# psc3m6 register map
Vendor: Infineon Technologies; Series: PSC3M6; File version: 1.0
CPU: CM33 r0p1, little endian, MPU, FPU, DSP, VTOR, 3 interrupt priority bits, 167 interrupts
Registers are 32-bit, read-write, reset 0x0 unless marked. A register's access mark holds for its fields unless they carry their own. Offsets are from the block's base; [hi:lo] are bit positions; lines under a group give offsets from that group; {n}, {i} and the like mark numbered series; 'fields as' and 'values as' point back to an identical list.

## TCPWM0 (part 1 of 2) — S40 Timer/Counter/PWM
Base 0x42A00000
{0x0+0x10000*i} GRP[{i}] (i=0..2) group — Group of counters
  {0x0+0x100*j} CNT[{j}] (j=0..7) group — Timer/Counter/PWM Counter Module
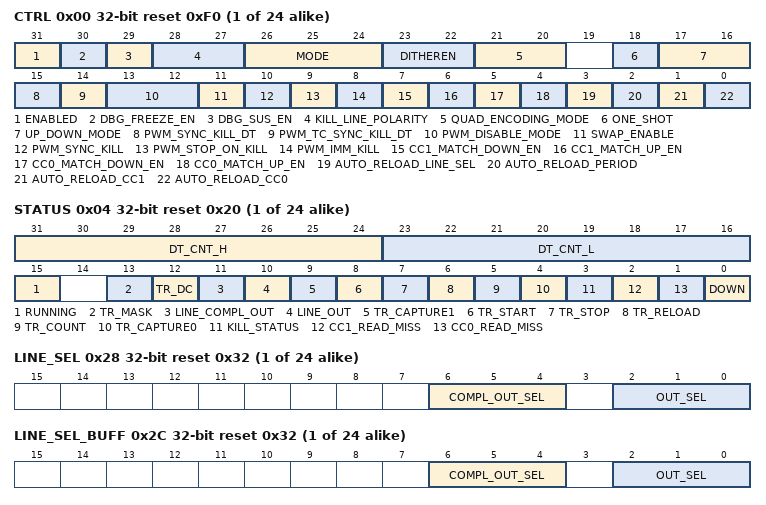
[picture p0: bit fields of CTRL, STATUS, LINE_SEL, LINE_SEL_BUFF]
    0x00 CTRL reset 0xF0 — Counter control register
      [31] ENABLED — Counter enable. '0': counter disabled. '1': counter enabled. Counter static configuration information (e.g. CTRL.MODE, all TR_IN_SEL, TR_IN_EDGE_SEL, TR_PWM_CTRL and TR_OUT_SEL register fields) should only be modified when the counter is disabled. When a counter is disabled, command and status information associated to the counter is cleared by HW, this includes: - the associated counter triggers in the CMD register are set to '0'. - the counter's interrupt cause fields in counter's INTR register. - the counter's status fields in counter's STATUS register.. - the counter's trigger outputs ('tr_out0' and tr_out1'). - the counter's line outputs ('line_out' and 'line_compl_out').
      [30] DBG_FREEZE_EN — Specifies the counter behavior in debug mode. '0': The counter operation depends on DBG_SUS_EN value, when ='0', counter operation continues; when ='1', Counter Freeze after roll over (tc event) and enters safe state. '1': The counter operation freezes in debug mode depending on DBG_SUS_EN value; when='0', Counter Freeze; when ='1', Counter Freeze immediately and enters safe state and running bit to be made ='0'. Safe state values are defined on line_out and line_compl_out by the corressponding kill_line_out_polarity and kill_line_compl_out_polarity
      [29] DBG_SUS_EN — Specifies the counter behavior in debug mode when suspend is enabled '0': The counter operation continues in debug mode as given by bit DBG_FREEZE_EN '1': The counter operation freezes in debug mode depending on DBG_FREEZE_EN value; when = '0', Counter Freeze after roll over (tc event) and enters safe state; when ='1', Counter Freeze immediately and enters safe state and running bit to be made ='0'. Safe state values are defined on line_out and line_compl_out by the corressponding kill_line_out_polarity and kill_line_compl_out_polarity
      [28:27] KILL_LINE_POLARITY — In PWM and PWM_DT modes, these two bits can be used to invert 'line_out' and 'line_compl_out' during kill mode
        0=KILL_LINE_POLARITY (When '0' it is disabled.); 1=KILL_LINE_OUT_POLARITY (When bit 0 is '1', inverts the suppressed 'line_out' during KILL (PWM/PWM_DT/PWM_DISABLE modes). In the debug mode the safe state of the line_out is defined by this bit value. 1 - line_out will be high...); 2=KILL_LINE_COMPL_OUT_POLARITY (When bit 1 is '1', inverts the suppressed 'line_comp_out' during KILL (PWM/PWM_DT/PWM_DISABLE modes). In the debug mode the safe state of the line_compl_out is defined by this bit value. 1 - line_compl_out will be high...)
      [26:24] MODE — Counter mode.
        0=TIMER (Timer mode); 1=RSVD1 (N/A); 2=CAPTURE (Capture mode); 3=QUAD (Quadrature mode); 4=PWM (Pulse width modulation (PWM) mode. HRPWM feature is supported in this mode through HRPWM_CTRL register.); 5=PWM_DT (PWM with deadtime insertion mode. HRPWM feature is supported in this mode through HRPWM_CTRL register.); 6=PWM_PR (Pseudo random pulse width modulation); 7=SR (Shift register mode.)
      [23:22] DITHEREN — When '0', dithering is disabled
        1=PERIOD_DITHEN (Period dithering is enabled); 2=DUTY_DITHEN (Duty dithering is enabled); 3=PER_DUTY_DITHEN (Period and Duty dithering is enabled)
      [21:20] QUAD_ENCODING_MODE — In QUAD mode this field selects the quadrature encoding mode (X1/X2/X4) or the Up / Down rotary counting mode. In PWM, PWM_DT, PWM_PR and SR modes, these two bits can be used to invert 'line_out' and 'line_compl_out'. Inversion is the last step in generation of 'line_out' and 'line_compl_out'; i.e. a disabled output line 'line_out' has the value QUAD_ENCODING_MODE[0] and a disabled output line 'line_compl_out' has the value QUAD_ENCODING_MODE[1]. In TIMER mode, QUAD_ENCODING_MODE[1:0] is used to enable count up/down based on falling edges, rising edge or level of external capture0 event.
        0=X1 encoding (QUAD mode) This encoding is identical with an up / down counting functionality of the following way: Rising edges of input phiA increment or decrement the counter depending on the state of input phiB (direction input); 1=X2 (X2 encoding (QUAD mode)); 2=X4 (X4 encoding (QUAD mode)); 3=UP_DOWN (Up / Down rotary counting mode. Input phiA increments the counter, input phiB decrements the counter. The trigger edge detection settings apply.)
      [18] ONE_SHOT — When '0', counter runs continuous. When '1', counter is turned off by hardware when a terminal count event is generated.
      [17:16] UP_DOWN_MODE — Determines counter direction. In QUAD mode this field acts as QUAD_RANGE_MODE field selecting between different counter range, reload value and compare / capture behavior.
        0=COUNT_UP (Count up (to PERIOD). An overflow event is generated when the counter changes from a state in which COUNTER equals PERIOD. A terminal count event is generated when the counter changes from a state in which COUNTER equals PERIOD.); 1=COUNT_DOWN (Count down (to '0'). An underflow event is generated when the counter changes from a state in which COUNTER equals '0'. A terminal count event is generated when the counter changes from a state in which COUNTER equals '0'.); 2=COUNT_UPDN1 (Count up (to PERIOD), then count down (to '0'). An overflow event is generated when the counter changes from a state in which COUNTER equals PERIOD. An underflow event is generated when the counter changes from a state in which COUNTER equals '0'. A terminal count event is generated when the counter changes from a state in which COUNTER equals '0'.); 3=COUNT_UPDN2 (Count up (to PERIOD), then count down (to '0'). An overflow event is generated when the counter changes from a state in which COUNTER equals PERIOD. An underflow event is generated when the counter changes from a state in which COUNTER equals '0'. A terminal count event is generated when the counter changes from a state in which COUNTER equals '0' AND when the counter changes from a state in which COUNTER equals PERIOD (this counter direction can be used for PWM functionality with asymmetrical updates).)
      [15] PWM_SYNC_KILL_DT — Specifies synchronous DT kill behavior: '1': synchronous DT kill mode: the kill event disables the 'line_out' immediately whereas 'line_compl_out' signals will be disable after dead time till the next terminal count event (synchronous DT kill). 'Line_out' and 'line_compl_out' get enable at next tc event after kill input is inactive. In synchronous DT kill mode, STOP_EDGE should be RISING_EDGE. '0': synchronous DT kill mode: Disable This field has a function in PWM_DT modes only. This field is only used when PWM_STOP_ON_KILL is '0'.
      [14] PWM_TC_SYNC_KILL_DT — Specifies TC synchronour DT kill behavior: '1': TC synchronous DT kill mode: the kill event disables the 'line_out' and 'line_compl_out' signals at the next terminal count event and till the next terminal count event (synchronous 3 kill). If dead time is enabled, output get disables after the tc event + dead time. 'Line_out' and 'line_comp_out' get enable at next tc event after input input is inactive In synchronous kill mode, STOP_EDGE should be RISING_EDGE. '0': TC synchronous DT kill mode: Disable This field has a function in PWM_DT modes only. This field is only used when PWM_STOP_ON_KILL is '0'.
      [13:12] PWM_DISABLE_MODE — Specifies the behavior of the PWM outputs 'line_out' and 'line_compl_out' while the TCPWM counter is disabled (CTRL.ENABLED='0') or stopped. Note: The output signal of this selection can be further modified by the immediate kill logic and line_out polarity settings (CTRL.QUAL_ENCODING_MODE).
        0=Z (The behavior is the same is in previous mxtcpwm (version 1).); 1=RETAIN (When the counter is disabled the PWM outputs 'line_out' and 'line_compl_out' are driven by the TCPWM. When the counter is disabled or stopped upon a stop event the PWM outputs are retained (keep their previous levels). While the counter is disabled or stopped the PWM outputs can be changed via LINE_SEL (when parameter GRP_SMC_PRESENT = 1).); 2=L (When the counter is disabled the PWM outputs 'line_out' and 'line_compl_out' are driven by the TCPWM. When the counter is disabled or stopped upon a stop event the PWM output 'line_out' is driven as a fixed '0' and the PWM output 'line_compl_out' is driven as a fixed '1'.); 3=H (When the counter is disabled the PWM outputs 'line_out' and 'line_compl_out' are driven by the TCPWM. When the counter is disabled or stopped upon a stop event the PWM output 'line_out' is driven as a fixed '1' and the PWM output 'line_compl_out' is driven as a fixed '0'.)
      [11] SWAP_ENABLE — Specifies whether swapping mechanism between CC0 and buffered CC0, CC1 and buffered CC1, PERIOD and buffered PERIOD, DT and buffered DT are disabled '0': shadow transfer mode '1': swap enable mode Note: Auto reload bit of the corresponsing register (CC), CC1 and Period) should be enabled for both shadow transfer mode and swap mode. DT register only supports shadow transfer mode.
      [10] PWM_SYNC_KILL — Specifies asynchronous/synchronous kill behavior: '1': synchronous kill mode: the kill event disables the 'line_out' and 'line_compl_out' signals immediately. 'Line_out' and 'Line_compl_out' will be enable at the next terminal count event (synchronous kill) after kill event is inactive. In synchronous kill mode, STOP_EDGE should be RISING_EDGE. '0': asynchronous kill mode: the kill event only disables the 'dt_line_out' and 'dt_line_compl_out' signals when present. In asynchronous kill mode, STOP_EDGE should be NO_EDGE_DET. This field has a function in PWM and PWM_DT modes only. This field is only used when PWM_STOP_ON_KILL is '0'.
      [9] PWM_STOP_ON_KILL — Specifies whether the counter stops on a kill events: '0': kill event does NOT stop counter. '1': kill event stops counter. This field has a function in PWM, PWM_DT and PWM_PR modes only.
      [8] PWM_IMM_KILL — Specifies whether the kill event immediately deactivates the 'line_out' and 'line_compl_out' signals or with the next module clock ('active count' pre-scaled 'clk_counter'). '0': synchronous kill activation. Deactivates the 'line_out' and 'line_compl_out' signals with the next module clock ('active count' pre-scaled 'clk_counter'). '1': immediate kill activation. Immediately deactivates the 'dt_line_out' and 'dt_line_compl_out' signals. This field has a function in PWM, PWM_DT and PWM_PR modes only.
      [7] CC1_MATCH_DOWN_EN — Enables / disables the compare match 1 event generation (COUNTER equals CC0 register) when counting down (STATUS.DOWN = 1) in CNT_UPDN1/2 mode. '0': compare match 1 event generation disabled when counting down '1': compare match 1 event generation enabled when counting down This field has a function in PWM and PWM_DT modes only.
      [6] CC1_MATCH_UP_EN — Enables / disables the compare match 1 event generation (COUNTER equals CC0 register) when counting up (STATUS.DOWN = 0) in CNT_UPDN1/2 mode. '0': compare match 1 event generation disabled when counting up '1': compare match 1 event generation enabled when counting up This field has a function in PWM and PWM_DT modes only.
      [5] CC0_MATCH_DOWN_EN — Enables / disables the compare match 0 event generation (COUNTER equals CC0 register) when counting down (STATUS.DOWN = 1) in CNT_UPDN1/2 mode. '0': compare match 0 event generation disabled when counting down '1': compare match 0 event generation enabled when counting down This field has a function in PWM and PWM_DT modes only.
      [4] CC0_MATCH_UP_EN — Enables / disables the compare match 0 event generation (COUNTER equals CC0 register) when counting up (STATUS.DOWN = 0) in CNT_UPDN1/2 mode. '0': compare match 0 event generation disabled when counting up '1': compare match 0 event generation enabled when counting up This field has a function in PWM and PWM_DT modes only.
      [3] AUTO_RELOAD_LINE_SEL — Specifies switching of the LINE_SEL and LINE_BUFF_SEL values. This field has a function in PWM and PWM_PR modes. '0': never switch. '1': switch on a terminal count event with and actively pending switch event.
      [2] AUTO_RELOAD_PERIOD — Specifies switching of the PERIOD and buffered PERIOD values. This field has a function in PWM and PWM_DT modes. '0': never switch. '1': switch on a terminal count event with and actively pending switch event. In QUAD mode, QUAD_RANGE0_CMP range mode this field is used to select the index / wrap-around capture function. '0': Captures on index (reload) event. The counter value is copied to the PERIOD register on an index (reload) event. '1': Captures when COUNTER equals 0 or 0xffff. The counter value is copied to the PERIOD register when COUNTER equals 0 or 0xffff.
      [1] AUTO_RELOAD_CC1 — Specifies switching of the CC1 and buffered CC1 values. This field has a function in TIMER, QUAD (QUAD_RANGE0_CMP, QUAD_RANGE1_CMP range modes), SR, PWM, PWM_DT and PWM_PR modes. Timer, QUAD, SR modes: '0': never switch. '1': switch on a compare match 1 event. PWM, PWM_DT, PWM_PR modes: '0: never switch. '1': switch on a terminal count event with an actively pending switch event.
      [0] AUTO_RELOAD_CC0 — Specifies switching of the CC0 and buffered CC0 values. This field has a function in TIMER, QUAD (QUAD_RANGE0_CMP, QUAD_RANGE1_CMP range modes), SR, PWM, PWM_DT and PWM_PR modes. Timer, QUAD, SR modes: '0': never switch. '1': switch on a compare match 0 event. PWM, PWM_DT, PWM_PR modes: '0: never switch. '1': switch on a terminal count event with an actively pending switch event.
    0x04 STATUS ro reset 0x20 — Counter status register
      [31:24] DT_CNT_H — High byte of 16-bit dead time counter. In PWM_DT mode, this counter is used for dead time insertion. In all other modes, this field has no effect. Note: This field only exists when parameter GRP_AMC_PRESENT for advanced motor control is set to 1. Otherwise the dead time is only 8bit wide and the only the field DT_CNT_L is used as dead time counter.
      [23:16] DT_CNT_L — Generic 8-bit counter field. In PWM_DT mode, this counter is used for dead time insertion (8bit dead time counter or low byte of 16-bit dead time counter).
      [15] RUNNING — When '0', the counter is NOT running. When '1', the counter is running. This field is used to indicate that the counter is running after a start/reload event and that the counter is stopped after a stop event. When a running counter operation is paused in debug state (see CTRL.DBG_PAUSE) then the RUNNING bit is still '1'.
      [13] TR_MASK — Indicates the actual level of the selected mask trigger.
      [12] TR_DC — Indicates the actual level of the selected DC trigger.
      [11] LINE_COMPL_OUT — Indicates the actual level of the complementary PWM line output signal.
      [10] LINE_OUT — Indicates the actual level of the PWM line output signal.
      [9] TR_CAPTURE1 — Indicates the actual level of the selected capture 1 trigger.
      [8] TR_START — Indicates the actual level of the selected start trigger.
      [7] TR_STOP — Indicates the actual level of the selected stop trigger.
      [6] TR_RELOAD — Indicates the actual level of the selected reload trigger.
      [5] TR_COUNT — Indicates the actual level of the selected count trigger.
      [4] TR_CAPTURE0 — Indicates the actual level of the selected capture 0 trigger.
      [3] KILL_STATUS — When '0', There is no kill event in pwm, pwm_dt ,pwm_pr ,sr operation When '1', There is kill event currently active in pwm, pwm_dt ,pwm_pr ,sr operation
      [2] CC1_READ_MISS — When '0', CPU did not miss reading capture1 event information When '1', CPU miss reading past capture1 event information
      [1] CC0_READ_MISS — When '0', CPU did not miss reading capture0 event information When '1', CPU miss reading past capture0 event information
      [0] DOWN — When '0', counter is counting up. When '1', counter is counting down. In QUAD mode, this field indicates the direction of the latest counter change: '0' when last incremented and '1' when last decremented.
    0x08 COUNTER — Counter count register
      [31:0] COUNTER — 16-bit / 32-bit counter value. It is advised to not write to this field when the counter is running.
    0x10 CC0 reset 0xFFFFFFFF — Counter compare/capture 0 register
      [31:0] CC — In CAPTURE mode, captures the counter value. In other modes, compared to counter value. In compare mode LSBs given by GRP_HRPWM_WIDTH is used for HRPWM generation when GRP_HRPWM_PRESENT ='1'.
    0x14 CC0_BUFF reset 0xFFFFFFFF — Counter buffered compare/capture 0 register
      [31:0] CC — Additional buffer for counter CC register. In compare mode LSBs given by GRP_HRPWM_WIDTH is used for HRPWM generation when GRP_HRPWM_PRESENT ='1'.
    0x18 CC1 reset 0xFFFFFFFF — Counter compare/capture 1 register
      fields as GRP[0].CNT[0].CC0
    0x1C CC1_BUFF reset 0xFFFFFFFF — Counter buffered compare/capture 1 register
      [31:0] CC — Additional buffer for counter CC1 register. In compare mode LSBs given by GRP_HRPWM_WIDTH is used for HRPWM generation when GRP_HRPWM_PRESENT ='1'.
    0x20 PERIOD reset 0xFFFFFFFF — Counter period register
      [31:0] PERIOD — Period value: upper value of the counter. When the counter should count for n cycles, this field should be set to n-1. In PWM and PWM_DT mode LSBs given by GRP_HRPWM_WIDTH is used for HRPWM generation when GRP_HRPWM_PRESENT ='1'.
    0x24 PERIOD_BUFF reset 0xFFFFFFFF — Counter buffered period register
      [31:0] PERIOD — Additional buffer for counter PERIOD register. In PWM_PR mode PEROD_BUFF defines the LFSR polynomial. Each bit represents a tap of the shift register which can be feed back to the MSB via an XOR tree. Examples for GRP_CNT_WIDTH = 16: - Maximum length 16bit LFSR - polynomial x^16 + x^14 + x^13 + x^11 + 1 - taps 0,2,3,5 -> PERIOD = 0x002d - period is 2^16-1 = 65535 cycles - Maximum length 8bit LFSR: - polynomial x^8 + x^6 + x^5 + x^4 + 1 - taps 8,10,11,12 (realized in 8 MSBs of 16bit LFSR) - period is 2^8-1 = 255 cycles In SR mode PERIOD_BUFF defines which tap of the shift register generates the PWM output signals. For a delay of n cycles (from capture event to PWM output) the bit CNT_WIDTH-n should be set to '1'. For a shift register function only one tap should be use, i.e. a one-hot value must be written to PERIOD_BUFF. If multiple bits in PERIOD_BUFF are set then the taps are XOR combined. In PWM and PWM_DT mode LSSBs given by GRP_HRPWM_WIDTH is used for HRPWM generation when GRP_HRPWM_PRESENT ='1'.
    0x28 LINE_SEL reset 0x32 — Counter line selection register
      [6:4] COMPL_OUT_SEL — Selects the source for the output signal 'line_compl_out'. Default setting is the inverted PWM signal 'line'. Other settings are useful for Stepper Motor Control. This field has a function in PWM, PWM_PR and PWM_DT modes only. Note: The output signal of this selection can be further modified by the stop / kill logic and line_compl_out polarity setting (CTRL.KILL_LINE_COMPL_OUT_POLARITY).
        0=L (fixed '0'); 1=H (fixed '1'. In PWM_DT mode, dead-time would be inserted on the posedge.); 2=PWM (PWM signal 'line_out'); 3=PWM_INV (inverted PWM signal 'line_compl_out'); 4=Z (The output 'line_compl_out' is not driven by the TCPWM. Instead the port default level configuration applies, e.g. 'Z' (high impedance). Note: This is realized by driving the output 'line_compl_out_en' to 0.); 5=MOTIF (The source for PWM signal conditioning comes from MOTIF modulation output control signals. 'line_compl_out' can be set to '0' , '1', PWM or PWM_INV.); 6=RSVD6 (N/A); 7=RSVD7 (N/A)
      [2:0] OUT_SEL — Selects the source for the output signal 'line_out'. Default setting is the PWM signal 'line'. Other settings are useful for Stepper Motor Control. This field has a function in PWM, PWM_PR, and PWM_DT modes only. Note: The output signal of this selection can be further modified by the stop / kill logic and line_out polarity setting (CTRL.KILL_LINE_OUT_POLARITY).
        0=L (fixed '0'); 1=H (fixed '1'. In PWM_DT mode, dead-time would be inserted in posedge.); 2=PWM (PWM signal 'line_out'); 3=PWM_INV (inverted PWM signal 'line_compl_out'); 4=Z (The output 'line_out' is not driven by the TCPWM. Instead the port default level configuration applies, e.g. 'Z' (high impedance). Note: This is realized by driving the output 'line_out_en' to 0.); 5=MOTIF (The source for PWM signal conditioning comes from MOTIF modulation output control signals. 'line_out' can be set to '0' , '1' , PWM or PWM_INV.); 6=RSVD6 (N/A); 7=RSVD7 (N/A)
    0x2C LINE_SEL_BUFF reset 0x32 — Counter buffered line selection register
      [6:4] COMPL_OUT_SEL — Buffer for LINE_SEL.COMPL.OUT_SEL. Can be exchanged with LINE_SEL.LINE_COMPL_OUT_SEL on a terminal count event with an actively pending switch event. This field has a function in PWM, PWM_PR and PWM_DT modes only.
      [2:0] OUT_SEL — Buffer for LINE_SEL.OUT_SEL. Can be exchanged with LINE_SEL.LINE_OUT_SEL on a terminal count event with an actively pending switch event. This field has a function in PWM, PWM_PR and PWM_DT modes only.
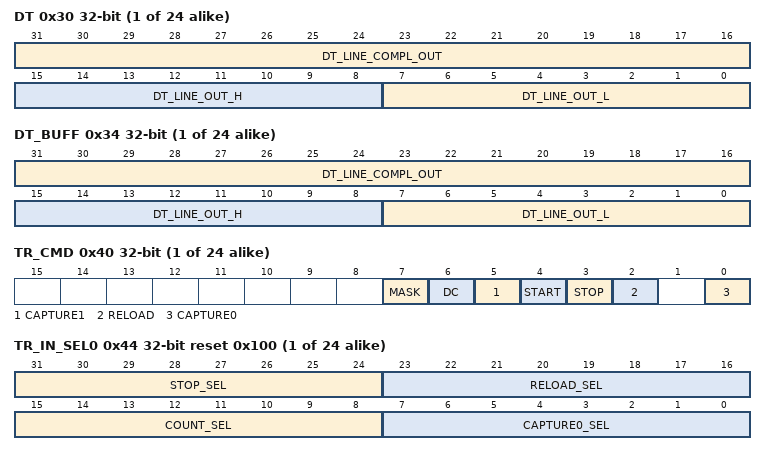
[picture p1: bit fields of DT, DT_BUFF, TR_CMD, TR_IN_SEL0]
    0x30 DT — Counter PWM dead time register
      [31:16] DT_LINE_COMPL_OUT — In PWM_DT mode, this field is used to determine the dead time before activating the complementary PWM line output signal 'line_compl_out': amount of dead time cycles in the counter clock domain. In all other modes, this field has no effect. In PWM_DT mode LSBs given by GRP_HRPWM_WIDTH is used for HRPWM generation when GRP_HRPWM_PRESENT ='1'. Note: This field only exists when parameter GRP_AMC_PRESENT for advanced motor control is set to 1. Otherwise the dead time is only 8 bit wide and the same dead time specified by field DT_LINE_OUT_L is used before activating 'line_out' and 'line_compl_out'.
      [15:8] DT_LINE_OUT_H — In PWM_DT mode, this field is used to determine the high byte of the dead time before activating the PWM line output signal 'line_out': amount of dead time cycles in the counter clock domain. In all other modes, this field has no effect. In PWM_DT mode LSBs given by GRP_HRPWM_WIDTH is used for HRPWM generation when GRP_HRPWM_PRESENT ='1'. Note: This field only exists when parameter GRP_AMC_PRESENT for advanced motor control is set to 1. Otherwise the dead time is only 8 bit wide and the same dead time specified by field DT_LINE_OUT_L is used before activating 'line_out' and 'line_compl_out'.
      [7:0] DT_LINE_OUT_L — In PWM_DT mode, this field is used to determine the low byte of the dead time before activating the PWM line output signal 'line_out': amount of dead time cycles in the counter clock domain. Note: This field determines the low byte of the 16-bit dead time before activating 'line_out' when parameter GRP_AMC_PRESENT for advanced motor control is set to 1. Otherwise the dead time is only 8 bit wide and the same dead time specified by this DT_LINE_OUT_L field is used before activating 'line_out' and 'line_compl_out'.
    0x34 DT_BUFF — Counter buffered PWM dead time register
      [31:16] DT_LINE_COMPL_OUT — Buffer for DT.DT_LINE_COMPL_OUT register Data will shadow transfer to DT.DT_LINE_COMPL_OUT on a terminal count event with an actively pending switch when CTRL.SWAP_ENABLE is set to 0. In PWM_DT mode, the data in this field will be shadow transfer to DT.DT_LINE_COMPL_OUT Note: This field only exists when parameter GRP_AMC_PRESENT for advanced motor control is set to 1. Otherwise, the dead time is only 8 bit wide and the same dead time specified by field DT_LINE_OUT_L is used. In PWM_DT mode LSBs given by GRP_HRPWM_WIDTH is used for HRPWM generation when GRP_HRPWM_PRESENT ='1'.
      [15:8] DT_LINE_OUT_H — Buffer for DT.DT_LINE_OUT_H register Data will shadow transfer to DT.DT_LINE_OUT_H on a terminal count event with an actively pending switch event when CTRL.SWAP_ENABLE is set to 0. In PWM_DT mode, the data in this field will be shadow transfer to DT.DT_LINE_OUT_H to determine the high byte of the dead time. In PWM_DT mode LSBs given by GRP_HRPWM_WIDTH is used for HRPWM generation when GRP_HRPWM_PRESENT ='1'. Note: This field only exists when parameter GRP_AMC_PRESENT for advanced motor control is set to 1. Otherwise, the dead time buffer is only 8 bit wide
      [7:0] DT_LINE_OUT_L — Buffer for DT.DT_LINE_OUT_L register Data will shadow transfer to DT.DT_LINE_OUT_L on a terminal count event with an actively pending switch event when CTRL.SWAP_ENABLE is set to 0. In PWM_DT mode, the data in this field will be shadow transfer to DT.DT_LINE_OUT_L to determine the low byte of the dead time Note: This field determines the low byte of the 16-bit dead time buffer when parameter GRP_AMC_PRESENT for advanced motor control is set to 1. Otherwise the dead time buffer is only 8 bit wide.
    0x38 PS — Counter prescalar register
      [2:0] PS_DIV — Select the pre-scaling of the selected counter clock. If HRPWM is intended to be used for the counter output, this value shall be set to default '0' else the HRPWM feature will not work.
        0=DIVBY1 (Pre-scaling of the selected counter clock. Divide by 1); 1=DIVBY2 (Pre-scaling of the selected counter clock. Divide by 2); 2=DIVBY4 (Pre-scaling of the selected counter clock. Divide by 4); 3=DIVBY8 (Pre-scaling of the selected counter clock. Divide by 8); 4=DIVBY16 (Pre-scaling of the selected counter clock. Divide by 16); 5=DIVBY32 (Pre-scaling of the selected counter clock. Divide by 32); 6=DIVBY64 (Pre-scaling of the selected counter clock. Divide by 64); 7=DIVBY128 (Pre-scaling of the selected counter clock. Divide by 128)
    0x40 TR_CMD — Counter trigger command register
      [7] MASK write-1-sets — SW external event trigge for maskingr. For HW behavior, see COUNTER_CAPTURE0 field.
      [6] DC write-1-sets — SW external event trigger for duty cycle control. For HW behavior, see COUNTER_CAPTURE0 field.
      [5] CAPTURE1 write-1-sets — SW capture 1 trigger. For HW behavior, see COUNTER_CAPTURE0 field.
      [4] START write-1-sets — SW start trigger. For HW behavior, see COUNTER_CAPTURE0 field.
      [3] STOP write-1-sets — SW stop trigger. For HW behavior, see COUNTER_CAPTURE0 field.
      [2] RELOAD write-1-sets — SW reload trigger. For HW behavior, see COUNTER_CAPTURE0 field.
      [0] CAPTURE0 write-1-sets — SW capture 0 trigger. When written with '1', a capture 0 trigger is generated and the HW sets the field to '0' when the SW trigger has taken effect. It should be noted that the HW operates on the counter frequency. If the counter is disabled through CTRL.ENABLED, the field is immediately set to '0'.
    0x44 TR_IN_SEL0 reset 0x100 — Counter input trigger selection register 0
      [31:24] STOP_SEL — Selects one of the 256 input triggers as a stop trigger. In PWM, PWM_DT and PWM_PR modes, this is the kill trigger. In these modes, the kill trigger is used to either temporarily block the PWM outputs (PWM_STOP_ON_KILL is '0') or stop the functionality (PWM_STOP_ON_KILL is '1'). For the PWM and PWM_DT modes, the blocking of the output signals can be asynchronous (STOP_EDGE should be NO_EDGE_DET) in which case the blocking is as long as the trigger is '1' or synchronous (STOP_EDGE should be RISING_EDGE) in which case it extends till the next terminal count event.
      [23:16] RELOAD_SEL — Selects one of the 256 input triggers as a reload trigger. In QUAD mode, this is the index or revolution pulse. In these modes, it will update the counter with 0x8000 (counter midpoint) or 0x0000 depending on the QUAD_RANGE_MODE.
      [15:8] COUNT_SEL — Selects one of the 256 input triggers as a count trigger. In QUAD mode, this is the first phase (phi A). Default setting selects input trigger 1, which is always '1'. Note: In the modes: TIMER, CAPTURE, PWM, PWM_DT, and SR, If the counter is externally triggered ( COUNT_SEL > 1), an external trigger will be required for each TR_CMD to execute. For example, a write to TR_CMD.START will not start the counter until the trigger selected by COUNT_SEL asserts. The next trigger will increment the counter since the counter is now running. This goes for all TR_CMD fields.
      [7:0] CAPTURE0_SEL — Selects one of the up to 256 input triggers as a capture0 trigger. Input trigger 0 is always '0' and input trigger 1 is always '1'. If existing, the one-to-one trigger inputs 'tr_one_cnt_in' (different to each counter) are selected by setting 2 and above. The settings above are used for the general purpose trigger inputs 'tr_all_cnt_in' connected to all counters selected. In the PWM, PWM_DT and PWM_PR modes this trigger is used to switch the values if the compare and period registers with their buffer counterparts.
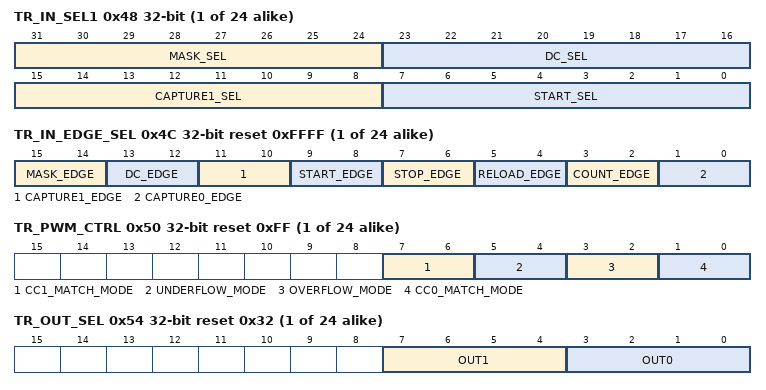
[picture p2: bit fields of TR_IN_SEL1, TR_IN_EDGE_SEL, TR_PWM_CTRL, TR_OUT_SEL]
    0x48 TR_IN_SEL1 — Counter input trigger selection register 1
      [31:24] MASK_SEL — Selects one of the 256 input triggers as mask input signal
      [23:16] DC_SEL — Selects one of the 256 input triggers as an external trigger for duty cycle control
      [15:8] CAPTURE1_SEL — Selects one of the 256 input triggers as a capture 1 trigger.
      [7:0] START_SEL — Selects one of the 256 input triggers as a start trigger. In QUAD mode, this is the second phase (phi B).
    0x4C TR_IN_EDGE_SEL reset 0xFFFF — Counter input trigger edge selection register
      [all] fields
        0=RISING_EDGE (Rising edge. Any rising edge generates an event.); 1=FALLING_EDGE (Falling edge. Any falling edge generates an event.); 2=ANY_EDGE (Rising AND falling edge. Any odd amount of edges generates an event.); 3=NO_EDGE_DET (No edge detection, use trigger as is.)
      [15:14] MASK_EDGE — An External Trigger event for masking PWM output.
      [13:12] DC_EDGE — An External Trigger event for duty cycle control.
      [11:10] CAPTURE1_EDGE — A capture 1 event will copy the counter value into the CC1 register.
      [9:8] START_EDGE — A start event will start the counter; i.e. the counter will become running. Starting does NOT enable the counter. A start event will not initialize the counter whereas the reload event does.
      [7:6] STOP_EDGE — A stop event, will stop the counter; i.e. it will no longer be running. Stopping will NOT disable the counter.
      [5:4] RELOAD_EDGE — A reload event will initialize the counter. When counting up, the counter is initialized to '0'. When counting down, the counter is initialized with PERIOD.
      [3:2] COUNT_EDGE — A counter event will increase or decrease the counter by '1'.
      [1:0] CAPTURE0_EDGE — A capture 0 event will copy the counter value into the CC0 register.
    0x50 TR_PWM_CTRL reset 0xFF — Counter trigger PWM control register
      [all] fields
        0=SET (Set to '1'); 1=CLEAR (Set to '0'); 2=INVERT; 3=NO_CHANGE
      [7:6] CC1_MATCH_MODE — Determines the effect of a compare match 1 event (COUNTER equals CC1 register) on the 'line_out' output signals.
      [5:4] UNDERFLOW_MODE — Determines the effect of a counter underflow event (COUNTER reaches '0') on the 'line_out' output signals.
      [3:2] OVERFLOW_MODE — Determines the effect of a counter overflow event (COUNTER reaches PERIOD) on the 'line_out' output signals.
      [1:0] CC0_MATCH_MODE — Determines the effect of a compare match 0 event (COUNTER equals CC0 register) on the 'line_out' output signals. Note that INVERT is especially useful for center aligned pulse width modulation. To generate a duty cycle of 0 percent, the counter CC0 register should be set to '0'. For a 100 percent duty cycle, the counter CC0 register should be set to larger than the counter PERIOD register.
    0x54 TR_OUT_SEL reset 0x32 — Counter output trigger selection register
      [7:4] OUT1 — Selects one of the internal events to generate the output trigger 1. Default setting selects the compare match 0 event.
        0=OVERFLOW (Overflow event); 1=UNDERFLOW (Underflow event); 2=TC (Terminal count event); 3=CC0_MATCH (Compare match 0 event (default selection)); 4=CC1_MATCH (Compare match 1 event); 5=LINE_OUT (PWM output signal 'line_out'); 6=CC0_CC1_MATCH (Compare match 0 event or Compare match 1 event); 7=MASK_OUT (PWM signal for masking the PWM output on another counter. When Masking is disabled, then same as LINE_OUT); 8=MASK_COMPL_OUT (Complimentary PWM signal for masking the PWM output on another counter. When Masking is disabled, then same as LINE_COMPL_OUT); 9=Disabled (Output trigger disabled.)
      [3:0] OUT0 — Selects one of the internal events to generate the output trigger 0. Default setting selects the terminal count event.
        0=OVERFLOW (Overflow event); 1=UNDERFLOW (Underflow event); 2=TC (Terminal count event (default selection)); 3=CC0_MATCH (Compare match 0 event); 4=CC1_MATCH (Compare match 1 event); 5=LINE_OUT (PWM output signal 'line_out'); 6=CC0_CC1_MATCH (Compare match 0 event or Compare match 1 event); 7=MASK_OUT (PWM signal for masking the PWM output on another counter. When Masking is disabled, then same as LINE_OUT); 8=MASK_COMPL_OUT (Complimentary PWM signal for masking the PWM output on another counter. When Masking is disabled, then same as LINE_COMPL_OUT); 9=Disabled (Output trigger disabled.)
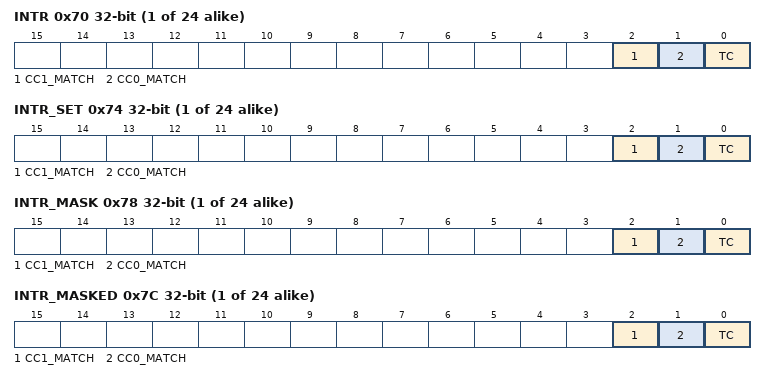
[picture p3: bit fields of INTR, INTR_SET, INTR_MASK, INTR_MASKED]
    0x70 INTR — Interrupt request register
      [2] CC1_MATCH write-1-clears — Counter matches CC1 register event. Set to '1', when event is detected. Write with '1' to clear bit.
      [1] CC0_MATCH write-1-clears — Counter matches CC0 register event. Set to '1', when event is detected. Write with '1' to clear bit.
      [0] TC write-1-clears — Terminal count event. Set to '1', when event is detected. Write with '1' to clear bit.
    0x74 INTR_SET — Interrupt set request register
      [2] CC1_MATCH write-1-sets — Write with '1' to set corresponding bit in interrupt request register.
      [1] CC0_MATCH write-1-sets — Write with '1' to set corresponding bit in interrupt request register.
      [0] TC write-1-sets — Write with '1' to set corresponding bit in interrupt request register.
    0x78 INTR_MASK — Interrupt mask register
      [2] CC1_MATCH — Mask bit for corresponding bit in interrupt request register.
      [1] CC0_MATCH — Mask bit for corresponding bit in interrupt request register.
      [0] TC — Mask bit for corresponding bit in interrupt request register.
    0x7C INTR_MASKED ro — Interrupt masked request register
      [2] CC1_MATCH — Logical and of corresponding request and mask bits.
      [1] CC0_MATCH — Logical and of corresponding request and mask bits.
      [0] TC — Logical and of corresponding request and mask bits.
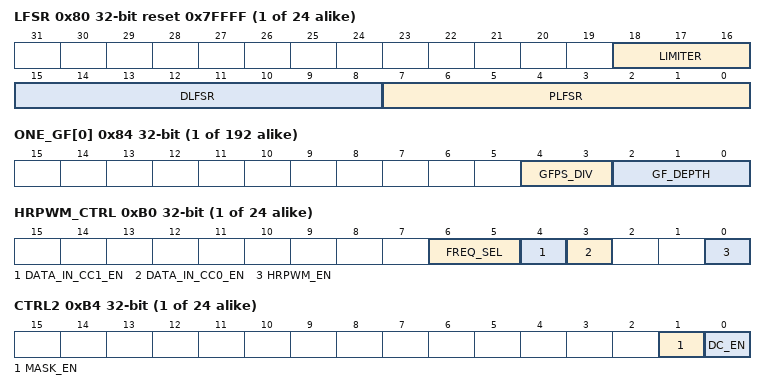
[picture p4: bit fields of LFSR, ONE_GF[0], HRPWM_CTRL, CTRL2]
    0x80 LFSR reset 0x7FFFF
      [18:16] LIMITER — Limiter register. It defines the magnitude of the pseudo-random value to be added to period/CC0/CC1. PLFSR[7]/DLFSR[7] is the sign polarity
        1=Limit_1 (When Limit_1 is '1', the PLFSR[0]/DLFSR[0] is magnitude of the value to be added to period/CC0/CC1); {v}=Limit_{v} (When Limit_{v} is '1', the PLFSR[{v-1}:0]/DLFSR[{v-1}:0] is magnitude of the value to be added to period/CC0/CC1) (v=2..7)
      [15:8] DLFSR — DLFSR register. DLFSR defines pseudo-random value for CC0/CC1. SW need to be initialized to non 0 (seed value) before dithering is enabled MSB of DLFSR will be the sign polarity. The magnitude of the randomness to be added to CC0/CC1 is in the range of -2^(N-1) to 2^(N-1)-1 where N is the width of the DLFSR register.
      [7:0] PLFSR — PLFSR register. PLFSR defines pseudo-random value for period. SW need to be initialized to non 0 (seed value) before dithering is enabled MSB of PLFSR will be the sign polarity. The magnitude of the randomness to be added to period is in the range of -2^(N-1) to 2^(N-1)-1 where N is the width of the PLFSR register
    {0x84+4k} ONE_GF[{k}] (k=0..7) — Glitch filter register for one to one trigger
      [4:3] GFPS_DIV — Select the glitch filter pre-scaling of the selected counter clock
        0=GFPS_DIVBY1 (Glitch filter pre-scaling of the selected counter clock. Divide by 1); 1=GFPS_DIVBY2 (Glitch filter pre-scaling of the selected counter clock. Divide by 2); 2=GFPS_DIVBY4 (Glitch filter pre-scaling of the selected counter clock. Divide by 4); 3=GFPS_DIVBY8 (Glitch filter pre-scaling of the selected counter clock. Divide by 8)
      [2:0] GF_DEPTH — Select the glitch filter depth
        0=DEPTHX0 (Glitch filter is turned off); 1=DEPTHX1 (Glitch filter depth is set to 1 x GFPS_DIVBYx of prescalar, where x is 1, 2, 4, 8); 2=DEPTHX2 (Glitch filter depth is set to 2 x GFPS_DIVBYx of prescalar, where x is 1, 2, 4, 8); 3=DEPTHX4 (Glitch filter depth is set to 4 x GFPS_DIVBYx of prescalar, where x is 1, 2, 4, 8); 4=DEPTHX8 (Glitch filter depth is set to 8 x GFPS_DIVBYx of prescalar, where x is 1, 2, 4, 8); 5=DEPTHX16 (Glitch filter depth is set to 16 x GFPS_DIVBYx of prescalar, where x is 1, 2, 4, 8); 6=DEPTHX32 (Glitch filter depth is set to 32 x GFPS_DIVBYx of prescalar, where x is 1, 2, 4, 8); 7=DEPTHX64 (Glitch filter depth is set to 64 x GFPS_DIVBYx of prescalar, where x is 1, 2, 4, 8)
    0xA4 TR_ONE_SYNC_BYPASS — Sync bypass register for one to one trigger
      [7:0] SYNC_BYPASS — When set='1', bypass the sync stage for the corresponding one to one trigger
    0xB0 HRPWM_CTRL — Counter control register for HRPWM feature
      [6:5] FREQ_SEL — Selects the frequency of operation of HRPWM feature. Microtick is adjusted based on this information. These bits specifies the frequency of CLK_OUT from TCPWM counter. CLK_OUT = CLK_PERI = CLK_HF3
        0=FREQ_SELX0 (CLK_OUT = 80 MHz or 100 MHz); 1=FREQ_SELX1 (CLK_OUT = 160MHz or 180 MHz); 2=FREQ_SELX2 (CLK_OUT = 200 MHz or 240 MHz); 3=FREQ_SELX3 (N/A)
      [4] DATA_IN_CC1_EN — When '1' parallel data path to register CC1 is active and bypass CC1 and CC1_BUFF register. AHB access to CC1 and CC1_BUFF is also disabled in this case. When this is set to 1, the data from data_in_cc1 get transfered immediately to the cc1 register. When '0' , the parallel data path is disabled and regular access over AHB is there.
      [3] DATA_IN_CC0_EN — When '1' parallel data path to register CC0 is active and bypass CC0 and CC0_BUFF register. AHB access to CC0 and CC0_BUFF is also disabled in this case. When this is set to 1, the data from data_in_cc0 get transfered immediately to the cc0 register. When '0' , the parallel data path is disabled and regular access over AHB is there.
      [0] HRPWM_EN — When '0' HRPWM feature is bypass, when '1' HRPWM feature is enabled. When enabled HRPWM feature is only available in PWM and PWM_DT mode. In other modes this bit will have no effect and HRPWM feature remain bypass
    0xB4 CTRL2 — Counter control register 2
      [1] MASK_EN — Define the External Mask Enable mode. Enabled when set to '1'
      [0] DC_EN — Define the External Trigger Event Mode for duty cycle control. Enabled when set to '1'
